AUTOSAR XML (schema 00050)
package /Diag_DtcSwc
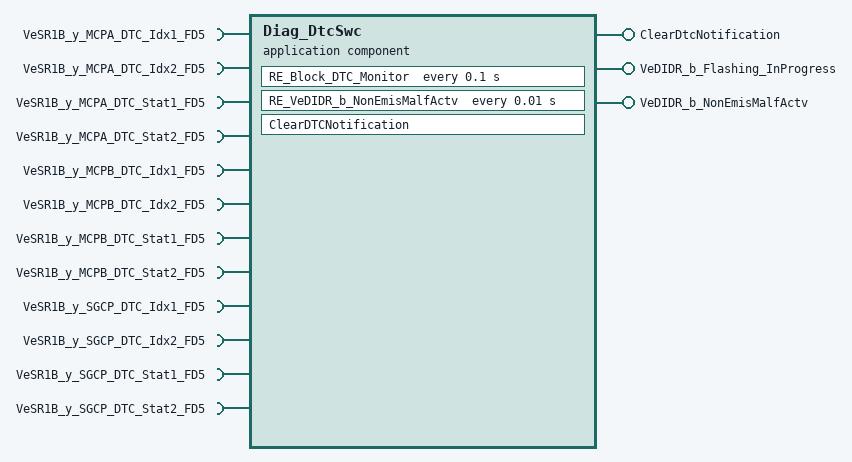
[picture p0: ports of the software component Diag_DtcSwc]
  application sw component type Diag_DtcSwc
    12 x require port:
      VeSR1B_y_MCPA_DTC_Idx1_FD5: nonqueued-receiver-com-spec{data-element=Value, init-value=VeCANR_y_MCPA_DTC_Idx1_FD5Value:0}, required-interface=VeSR1B_y_MCPA_DTC_Idx1_FD5
      VeSR1B_y_MCPA_DTC_Idx2_FD5: nonqueued-receiver-com-spec{data-element=Value, init-value=VeCANR_y_MCPA_DTC_Idx2_FD5Value:0}, required-interface=VeSR1B_y_MCPA_DTC_Idx2_FD5
      VeSR1B_y_MCPA_DTC_Stat1_FD5: nonqueued-receiver-com-spec{data-element=Value, init-value=VeCANR_e_MCPA_DTC_Stat1_FD5Value:0}, required-interface=VeSR1B_y_MCPA_DTC_Stat1_FD5
      VeSR1B_y_MCPA_DTC_Stat2_FD5: nonqueued-receiver-com-spec{data-element=Value, init-value=short-label=VeCANR_e_MCPA_DTC_Stat2_FD5Value}, required-interface=VeSR1B_y_MCPA_DTC_Stat2_FD5
      VeSR1B_y_MCPB_DTC_Idx1_FD5: nonqueued-receiver-com-spec{data-element=Value, init-value=VeCANR_y_MCPB_DTC_Idx1_FD5Value:0}, required-interface=VeSR1B_y_MCPB_DTC_Idx1_FD5
      VeSR1B_y_MCPB_DTC_Idx2_FD5: nonqueued-receiver-com-spec{data-element=Value, init-value=NumericalValueSpecification_0:0}, required-interface=VeSR1B_y_MCPB_DTC_Idx2_FD5
      VeSR1B_y_MCPB_DTC_Stat1_FD5: nonqueued-receiver-com-spec{data-element=Value, init-value=NumericalValueSpecification_0:0}, required-interface=VeSR1B_y_MCPB_DTC_Stat1_FD5
      VeSR1B_y_MCPB_DTC_Stat2_FD5: nonqueued-receiver-com-spec{data-element=Value, init-value=NumericalValueSpecification_0:0}, required-interface=VeSR1B_y_MCPB_DTC_Stat2_FD5
      VeSR1B_y_SGCP_DTC_Idx1_FD5: nonqueued-receiver-com-spec{data-element=Value, init-value=NumericalValueSpecification_0:0}, required-interface=VeSR1B_y_SGCP_DTC_Idx1_FD5
      VeSR1B_y_SGCP_DTC_Idx2_FD5: nonqueued-receiver-com-spec{data-element=Value, init-value=NumericalValueSpecification_0:0}, required-interface=VeSR1B_y_SGCP_DTC_Idx2_FD5
      VeSR1B_y_SGCP_DTC_Stat1_FD5: nonqueued-receiver-com-spec{data-element=Value, init-value=NumericalValueSpecification_0:0}, required-interface=VeSR1B_y_SGCP_DTC_Stat1_FD5
      VeSR1B_y_SGCP_DTC_Stat2_FD5: nonqueued-receiver-com-spec{data-element=Value, init-value=NumericalValueSpecification_0:0}, required-interface=VeSR1B_y_SGCP_DTC_Stat2_FD5
    provide port ClearDtcNotification: provided-interface=ClearDtcNotification
    provide port VeDIDR_b_Flashing_InProgress: provided-interface=VeDIDR_b_Flashing_InProgress
    provide port VeDIDR_b_NonEmisMalfActv: provided-interface=VeDIDR_b_NonEmisMalfActv
    behavior SwcInternalBehavior_0: data-type-mapping=[ADTtoIDTMapping, ADTtoIDTMapping, ADTtoIDTMapping]
      timing event TE_Block_DTC_Monitor: start-on-event=RE_Block_DTC_Monitor, period=0.1
      operation invoked event Op_ClearDTCNotification: start-on-event=ClearDTCNotification, operation=ClearDtcNotification.ClearDtcNotification
      timing event TE_VeDIDR_b_NonEmisMalfActv: start-on-event=RE_VeDIDR_b_NonEmisMalfActv, period=0.01
      runnable RE_Block_DTC_Monitor: symbol=RE_Block_DTC_Monitor_func
        data-receive-point-by-arguments:
          12 x access:
            DRP_VeCANR_e_MCPB_DTC_Stat1_FD5_VeCANR_e_MCPB_DTC_Stat1_FD5: accessed-variable=VeSR1B_y_MCPB_DTC_Stat1_FD5.Value
            DRP_VeCANR_e_MCPA_DTC_Stat1_FD5_VeCANR_e_MCPA_DTC_Stat1_FD5: accessed-variable=VeSR1B_y_MCPA_DTC_Stat1_FD5.Value
            DRP_VeCANR_y_MCPA_DTC_Idx1_FD5_VeCANR_y_MCPA_DTC_Idx1_FD5: accessed-variable=VeSR1B_y_MCPA_DTC_Idx1_FD5.Value
            DRP_VeCANR_y_MCPA_DTC_Idx2_FD5_VeCANR_y_MCPA_DTC_Idx2_FD5: accessed-variable=VeSR1B_y_MCPA_DTC_Idx2_FD5.Value
            DRP_VeCANR_e_MCPB_DTC_Stat2_FD5_VeCANR_e_MCPB_DTC_Stat2_FD5: accessed-variable=VeSR1B_y_MCPB_DTC_Stat2_FD5.Value
            DRP_VeCANR_y_SGCP_DTC_Idx2_FD5_VeCANR_y_SGCP_DTC_Idx2_FD5: accessed-variable=VeSR1B_y_SGCP_DTC_Idx2_FD5.Value
            DRP_VeCANR_e_MCPA_DTC_Stat2_FD5_VeCANR_e_MCPA_DTC_Stat2_FD5: accessed-variable=VeSR1B_y_MCPA_DTC_Stat2_FD5.Value
            DRP_VeCANR_e_SGCP_DTC_Stat2_FD5_VeCANR_e_SGCP_DTC_Stat2_FD5: accessed-variable=VeSR1B_y_SGCP_DTC_Stat2_FD5.Value
            DRP_VeCANR_y_SGCP_DTC_Idx1_FD5_VeCANR_y_SGCP_DTC_Idx1_FD5: accessed-variable=VeSR1B_y_SGCP_DTC_Idx1_FD5.Value
            DRP_VeCANR_y_MCPB_DTC_Idx1_FD5_VeCANR_y_MCPB_DTC_Idx1_FD5: accessed-variable=VeSR1B_y_MCPB_DTC_Idx1_FD5.Value
            DRP_VeCANR_y_MCPB_DTC_Idx2_FD5_VeCANR_y_MCPB_DTC_Idx2_FD5: accessed-variable=VeSR1B_y_MCPB_DTC_Idx2_FD5.Value
            DRP_VeCANR_e_SGCP_DTC_Stat1_FD5_VeCANR_e_SGCP_DTC_Stat1_FD5: accessed-variable=VeSR1B_y_SGCP_DTC_Stat1_FD5.Value
      runnable ClearDTCNotification
      runnable RE_VeDIDR_b_NonEmisMalfActv: symbol=RE_VeDIDR_b_NonEmisMalfActv_func
        data-send-points:
          access DSP_VeDIDR_b_NonEmisMalfActv_0: accessed-variable=VeDIDR_b_NonEmisMalfActv.VeDIDR_b_NonEmisMalfActv
          access DSP_VeDIDR_b_Flashing_InProgress_0: accessed-variable=VeDIDR_b_Flashing_InProgress.VeDIDR_b_Flashing_InProgress
